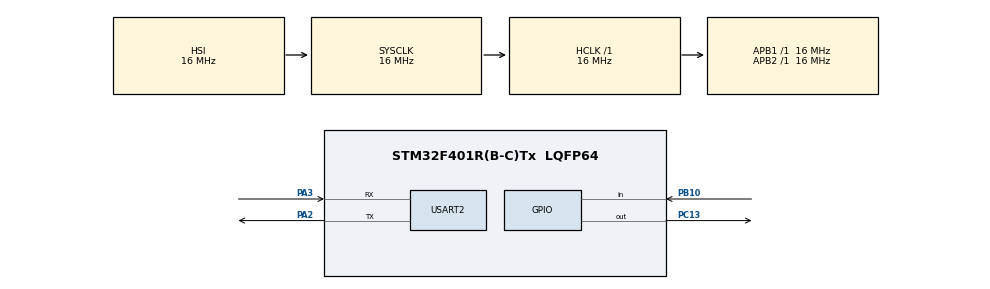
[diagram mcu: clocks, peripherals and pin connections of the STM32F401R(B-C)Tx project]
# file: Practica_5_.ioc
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Mcu.Family=STM32F4
Mcu.Name=STM32F401R(B-C)Tx
Mcu.Package=LQFP64
NVIC.PriorityGroup=NVIC_PRIORITYGROUP_4
PA2.Mode=Asynchronous
PA2.Signal=USART2_TX
PA3.Mode=Asynchronous
PA3.Signal=USART2_RX
PB10.GPIO_PuPd=GPIO_PULLDOWN
PB10.Signal=GPIO_Input
PC13-ANTI_TAMP.Signal=GPIO_Output
ProjectManager.HeapSize=0x200
ProjectManager.StackSize=0x400
ProjectManager.TargetToolchain=STM32CubeIDE
RCC.AHBFreq_Value=16000000
RCC.APB1Freq_Value=16000000
RCC.APB2Freq_Value=16000000
RCC.CortexFreq_Value=16000000
RCC.HSE_VALUE=25000000
RCC.HSI_VALUE=16000000
RCC.LSE_VALUE=32768
RCC.SYSCLKFreq_VALUE=16000000
RCC.VCOOutputFreq_Value=192000000
USART2.VirtualMode=VM_ASYNC
board=custom

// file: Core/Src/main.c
/* USER CODE BEGIN Header */
/**
  ******************************************************************************
  * @file           : main.c
  * @brief          : Main program body
  ******************************************************************************
  * @attention
  *
  * Copyright (c) 2023 STMicroelectronics.
  * All rights reserved.
  *
  * This software is licensed under terms that can be found in the LICENSE file
  * in the root directory of this software component.
  * If no LICENSE file comes with this software, it is provided AS-IS.
  *
  ******************************************************************************
  */
/* USER CODE END Header */
#include "main.h"
#include "usart.h"
#include "gpio.h"

/* USER CODE BEGIN Includes */
#include "API_delay.h"
#include "API_debounce.h"
#include "stm32f4xx_hal.h"
#include "API_uart.h"
/* USER CODE END Includes */

void SystemClock_Config(void);

int main(void)
{

  /* MCU Configuration--------------------------------------------------------*/

  /* Reset of all peripherals, Initializes the Flash interface and the Systick. */
  HAL_Init();

  /* Configure the system clock */
  SystemClock_Config();

  /* Initialize all configured peripherals */
  MX_GPIO_Init();
  MX_USART2_UART_Init();
  /* USER CODE BEGIN 2 */
  uartInit(); //Inicializa parámetros de UART2
  debounceFSM_Init(); //inicialización de la MEF
  /* USER CODE END 2 */

  /* Infinite loop */
  /* USER CODE BEGIN WHILE */
  while (1)
  {

	  debounceFSM_Update(); //actualiza la MEF

	  	  if(readKeyDesc())
	  	  {
	  		//crea una cadena char y envía el texto descrito para Flanco Descendente
	  		char TXT_BUTTON[]= "F_DESC"; //crea una cadena char y envía el texto descrito para Flanco Descendente
	  		uartSendString(TXT_BUTTON);

	  	  }

	  	if(readKeyAsc())
	  		  	  {
	  		//crea una cadena char y envía el texto descrito para Flanco Ascendente
	  		  		char TXT_BUTTON[]= "F_ASCE";
	  		  	    uartSendString(TXT_BUTTON);

	  		  	  }

    /* USER CODE END WHILE */

  }
}

void SystemClock_Config(void)
{
  RCC_OscInitTypeDef RCC_OscInitStruct = {0};
  RCC_ClkInitTypeDef RCC_ClkInitStruct = {0};

  /** Configure the main internal regulator output voltage
  */
  __HAL_RCC_PWR_CLK_ENABLE();
  __HAL_PWR_VOLTAGESCALING_CONFIG(PWR_REGULATOR_VOLTAGE_SCALE2);

  /** Initializes the RCC Oscillators according to the specified parameters
  * in the RCC_OscInitTypeDef structure.
  */
  RCC_OscInitStruct.OscillatorType = RCC_OSCILLATORTYPE_HSI;
  RCC_OscInitStruct.HSIState = RCC_HSI_ON;
  RCC_OscInitStruct.HSICalibrationValue = RCC_HSICALIBRATION_DEFAULT;
  RCC_OscInitStruct.PLL.PLLState = RCC_PLL_NONE;
  if (HAL_RCC_OscConfig(&RCC_OscInitStruct) != HAL_OK)
  {
    Error_Handler();
  }

  /** Initializes the CPU, AHB and APB buses clocks
  */
  RCC_ClkInitStruct.ClockType = RCC_CLOCKTYPE_HCLK|RCC_CLOCKTYPE_SYSCLK
                              |RCC_CLOCKTYPE_PCLK1|RCC_CLOCKTYPE_PCLK2;
  RCC_ClkInitStruct.SYSCLKSource = RCC_SYSCLKSOURCE_HSI;
  RCC_ClkInitStruct.AHBCLKDivider = RCC_SYSCLK_DIV1;
  RCC_ClkInitStruct.APB1CLKDivider = RCC_HCLK_DIV1;
  RCC_ClkInitStruct.APB2CLKDivider = RCC_HCLK_DIV1;

  if (HAL_RCC_ClockConfig(&RCC_ClkInitStruct, FLASH_LATENCY_0) != HAL_OK)
  {
    Error_Handler();
  }
}

void Error_Handler(void)
{
  __disable_irq();
  while (1)
  {
  }
}
